AUTOSAR XML (schema 4-2-2)
package /Components
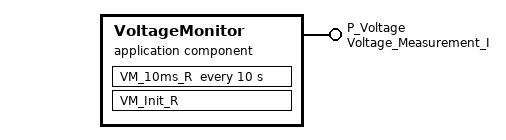
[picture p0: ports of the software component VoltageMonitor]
  application sw component type VoltageMonitor
    provide port P_Voltage: provided-interface=Voltage_Measurement_I
    behavior VoltageMonitor_InternalBehavior
      init event VM_Init_Event: start-on-event=VM_Init_R
      timing event VM_10ms_Event: start-on-event=VM_10ms_R, period=10
      runnable VM_Init_R
        data-send-points:
          access VA_VM_Init_Voltage: accessed-variable=P_Voltage.voltage_mV
      runnable VM_10ms_R: minimum-start-interval=10
        data-send-points:
          access VA_VM_Periodic_Voltage: accessed-variable=P_Voltage.voltage_mV
